VERSION "K24_6MT"

NS_ :

BS_:

BU_: PCM UNKNOWN VSA

BO_ 145 VSA_0x091: 8 VSA
 SG_ YAW_RATE_SENSOR : 7|10@0+ (1,0) [0|1023] "raw"  PCM
 SG_ UNKNOWN_1 : 13|8@0+ (1,0) [0|255] ""  PCM
 SG_ LATERAL_ACCELERATION_SENSOR : 19|10@0+ (1,0) [0|1023] "raw"  PCM
 SG_ UNKNOWN_2 : 20|2@1+ (1,0) [0|3] ""  PCM
 SG_ LONGITUDINAL_ACCELERATION_SENSOR : 25|10@0+ (1,0) [0|1023] "raw"  PCM
 SG_ UNKNOWN_3 : 40|4@1+ (1,0) [0|15] ""  PCM
 SG_ LONGITUDINAL_FAULT_SUMMARY : 44|1@1+ (1,0) [0|1] ""  PCM
 SG_ LATERAL_FAULT_SUMMARY : 45|1@1+ (1,0) [0|1] ""  PCM
 SG_ MONITOR_SUMMARY0 : 46|1@1+ (1,0) [0|1] ""  PCM
 SG_ YAW_FAULT_SUMMARY : 47|1@1+ (1,0) [0|1] ""  PCM
 SG_ MONITOR_CONDITION2 : 48|1@1+ (1,0) [0|1] ""  PCM
 SG_ MONITOR_SUMMARY1 : 49|1@1+ (1,0) [0|1] ""  PCM
 SG_ UNKNOWN_4 : 50|2@1+ (1,0) [0|3] ""  PCM
 SG_ LONGITUDINAL_FAULT_CONDITION : 52|1@1+ (1,0) [0|1] ""  PCM
 SG_ LATERAL_FAULT_CONDITION : 53|1@1+ (1,0) [0|1] ""  PCM
 SG_ MONITOR_CONDITION0 : 54|1@1+ (1,0) [0|1] ""  PCM
 SG_ YAW_FAULT_CONDITION : 55|1@1+ (1,0) [0|1] ""  PCM
 SG_ CHECKSUM : 56|4@1+ (1,0) [0|15] ""  PCM
 SG_ COUNTER : 60|2@1+ (1,0) [0|3] ""  PCM
 SG_ STATUS_BIT_1 : 62|1@1+ (1,0) [0|1] ""  PCM
 SG_ SCALAR_NOT_READY : 63|1@1+ (1,0) [0|1] ""  PCM
VAL_ 145 SCALAR_NOT_READY 1 "NOT_READY" ;

BO_ 420 VSA_0x1A4: 8 VSA
 SG_ MASTER_CYLINDER_PRESSURE_RAW : 3|12@0+ (1,0) [0|4095] "raw"  PCM
 SG_ PRESSURE_RELATED_INHIBIT_1 : 4|1@1+ (1,0) [0|1] ""  PCM
 SG_ PRESSURE_RELATED_INHIBIT_2 : 5|1@1+ (1,0) [0|1] ""  PCM
 SG_ UNKNOWN_1 : 6|2@1+ (1,0) [0|3] ""  PCM
 SG_ VSA_INTERVENTION_ACTIVE : 16|1@1+ (1,0) [0|1] ""  PCM
 SG_ ABS_INTERVENTION_ACTIVE : 17|1@1+ (1,0) [0|1] ""  PCM
 SG_ STATUS_BIT_1 : 18|1@1+ (1,0) [0|1] ""  PCM
 SG_ STATUS_BIT_2 : 19|1@1+ (1,0) [0|1] ""  PCM
 SG_ IDLE_STOP_INHIBIT_VSACASEN : 20|1@1+ (1,0) [0|1] ""  PCM
 SG_ STATUS_BIT_3 : 21|1@1+ (1,0) [0|1] ""  PCM
 SG_ STATUS_BIT_4 : 22|1@1+ (1,0) [0|1] ""  PCM
 SG_ COMPUTER_BRAKING_TBD : 23|1@1+ (1,0) [0|1] ""  PCM
 SG_ UNKNOWN_2 : 24|4@1+ (1,0) [0|15] ""  PCM
 SG_ VSA_DISABLED_TBD : 28|1@1+ (1,0) [0|1] ""  PCM
 SG_ STATUS_BIT_5 : 29|1@1+ (1,0) [0|1] ""  PCM
 SG_ VSA_SYSTEM_UNAVAILABLE_TBD : 30|1@1+ (1,0) [0|1] ""  PCM
 SG_ STATUS_BIT_6 : 31|1@1+ (1,0) [0|1] ""  PCM
 SG_ UNKNOWN_3 : 32|2@1+ (1,0) [0|3] ""  PCM
 SG_ VSA_WATCHDOG_REFRESH_REQUEST : 34|1@1+ (1,0) [0|1] ""  PCM
 SG_ UNKNOWN_4 : 35|5@1+ (1,0) [0|31] ""  PCM
 SG_ UNKNOWN_5 : 40|4@1+ (1,0) [0|15] ""  PCM
 SG_ IDLE_STOP_BRAKE_TRANSITION_TBD : 44|1@1+ (1,0) [0|1] ""  PCM
 SG_ UNKNOWN_6 : 45|3@1+ (1,0) [0|7] ""  PCM
 SG_ UNKNOWN_7 : 48|4@1+ (1,0) [0|15] ""  PCM
 SG_ BRAKE_HOLD_RELATED_TBD : 52|1@1+ (1,0) [0|1] ""  PCM
 SG_ STATUS_BIT_7 : 53|1@1+ (1,0) [0|1] ""  PCM
 SG_ STATUS_BIT_8 : 54|1@1+ (1,0) [0|1] ""  PCM
 SG_ STATUS_BIT_9 : 55|1@1+ (1,0) [0|1] ""  PCM
 SG_ CHECKSUM : 56|4@1+ (1,0) [0|15] ""  PCM
 SG_ COUNTER : 60|2@1+ (1,0) [0|3] ""  PCM
 SG_ STATUS_BIT_10 : 62|1@1+ (1,0) [0|1] ""  PCM
 SG_ STATUS_BIT_11 : 63|1@1+ (1,0) [0|1] ""  PCM
VAL_ 420 IDLE_STOP_INHIBIT_VSACASEN 0 "NORMAL" 1 "INHIBITED" ;

BO_ 426 XXX_0x1AA: 8 VSA
 SG_ UNKNOWN_1 : 7|16@0- (1,0) [-32768|32767] "raw"  PCM
 SG_ UNKNOWN_2 : 16|2@1+ (1,0) [0|3] ""  PCM
 SG_ UNKNOWN_3 : 18|2@1+ (1,0) [0|3] ""  PCM
 SG_ VSA_CATEGORY_STATE_TBD : 20|4@1+ (1,0) [0|15] ""  PCM
 SG_ UNKNOWN_4 : 24|3@1+ (1,0) [0|7] ""  PCM
 SG_ STATUS_BIT_1 : 27|1@1+ (1,0) [0|1] ""  PCM
 SG_ UNKNOWN_5 : 28|4@1+ (1,0) [0|15] ""  PCM
 SG_ UNKNOWN_6 : 32|8@1+ (1,0) [0|255] ""  PCM
 SG_ UNKNOWN_7 : 40|2@1+ (1,0) [0|3] ""  PCM
 SG_ STATUS_BIT_2 : 42|1@1+ (1,0) [0|1] ""  PCM
 SG_ IDLE_STOP_INHIBIT_STARTING_ASSIST_BRAKE : 43|1@1+ (1,0) [0|1] ""  PCM
 SG_ UNKNOWN_8 : 44|2@1+ (1,0) [0|3] ""  PCM
 SG_ STATUS_BIT_3 : 46|1@1+ (1,0) [0|1] ""  PCM
 SG_ IDLE_STOP_INHIBIT_ABS_VSA_UNIT : 47|1@1+ (1,0) [0|1] ""  PCM
 SG_ UNKNOWN_9 : 48|8@1+ (1,0) [0|255] ""  PCM
 SG_ CHECKSUM : 56|4@1+ (1,0) [0|15] ""  PCM
 SG_ COUNTER : 60|2@1+ (1,0) [0|3] ""  PCM
 SG_ STATUS_BIT_4 : 62|1@1+ (1,0) [0|1] ""  PCM
 SG_ STATUS_BIT_5 : 63|1@1+ (1,0) [0|1] ""  PCM
VAL_ 426 IDLE_STOP_INHIBIT_ABS_VSA_UNIT 0 "NORMAL" 1 "INHIBITED" ;
VAL_ 426 IDLE_STOP_INHIBIT_STARTING_ASSIST_BRAKE 0 "INHIBITED" 1 "NORMAL" ;

BO_ 432 VSA_0x1B0: 7 VSA
 SG_ UNKNOWN_1 : 0|8@1+ (1,0) [0|255] ""  PCM
 SG_ UNKNOWN_2 : 8|4@1+ (1,0) [0|15] ""  PCM
 SG_ WHEELS_MOVING : 12|1@1+ (1,0) [0|1] ""  PCM
 SG_ UNKNOWN_3 : 13|2@1+ (1,0) [0|3] ""  PCM
 SG_ STATUS_BIT_1 : 15|1@1+ (1,0) [0|1] ""  PCM
 SG_ UNKNOWN_4 : 16|8@1+ (1,0) [0|255] ""  PCM
 SG_ UNKNOWN_5 : 24|8@1+ (1,0) [0|255] ""  PCM
 SG_ UNKNOWN_6 : 32|3@1+ (1,0) [0|0] ""  PCM
 SG_ STANDSTILL_BRAKE_STATUS_D4B3_TBD : 35|1@1+ (1,0) [0|0] ""  PCM
 SG_ STANDSTILL_BRAKE_STATUS_D4B4_TBD : 36|1@1+ (1,0) [0|0] ""  PCM
 SG_ STANDSTILL_BRAKE_STATUS_D4B5_TBD : 37|1@1+ (1,0) [0|0] ""  PCM
 SG_ STANDSTILL_BRAKE_STATUS_D4B6_TBD : 38|1@1+ (1,0) [0|0] ""  PCM
 SG_ STATUS_BIT_2 : 39|1@1+ (1,0) [0|0] ""  PCM
 SG_ STANDSTILL_STATUS_D5B0_TBD : 40|1@1+ (1,0) [0|0] ""  PCM
 SG_ STANDSTILL_STATUS_D5B1_TBD : 41|1@1+ (1,0) [0|0] ""  PCM
 SG_ STANDSTILL_STATE_D5_BITS3_2_TBD : 42|2@1+ (1,0) [0|0] ""  PCM
 SG_ UNKNOWN_7 : 44|4@1+ (1,0) [0|0] ""  PCM
 SG_ CHECKSUM : 48|4@1+ (1,0) [0|15] ""  PCM
 SG_ COUNTER : 52|2@1+ (1,0) [0|3] ""  PCM
 SG_ PROTOCOL_FLAGS : 54|2@1+ (1,0) [0|3] ""  PCM

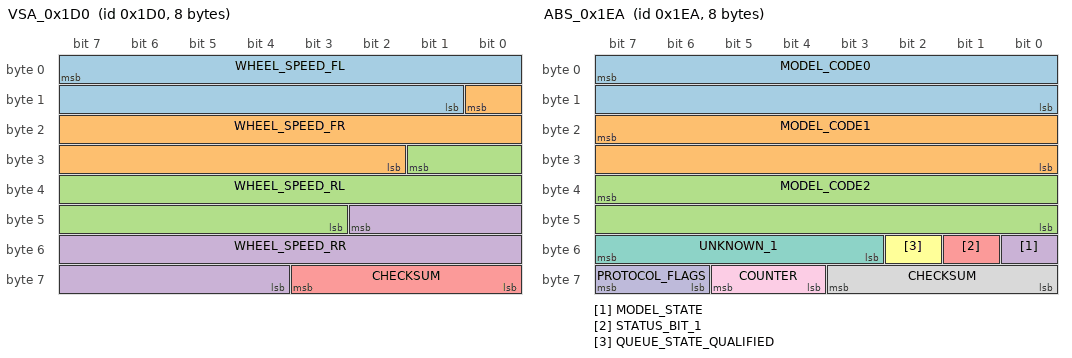
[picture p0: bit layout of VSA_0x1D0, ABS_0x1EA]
BO_ 464 VSA_0x1D0: 8 VSA
 SG_ WHEEL_SPEED_FL : 7|15@0+ (0.00993422,0) [0|325.51458674] "km/h"  PCM
 SG_ WHEEL_SPEED_FR : 8|15@0+ (0.00993422,0) [0|325.51458674] "km/h"  PCM
 SG_ WHEEL_SPEED_RL : 25|15@0+ (0.00993422,0) [0|325.51458674] "km/h"  PCM
 SG_ WHEEL_SPEED_RR : 42|15@0+ (0.00993422,0) [0|325.51458674] "km/h"  PCM
 SG_ CHECKSUM : 56|4@1+ (1,0) [0|15] ""  PCM

BO_ 490 ABS_0x1EA: 8 VSA
 SG_ MODEL_CODE0 : 7|16@0+ (1,0) [0|65535] "raw"  UNKNOWN
 SG_ MODEL_CODE1 : 23|16@0+ (1,0) [0|65535] "raw"  UNKNOWN
 SG_ MODEL_CODE2 : 39|16@0+ (1,0) [0|65535] "raw"  UNKNOWN
 SG_ MODEL_STATE : 48|1@1+ (1,0) [0|1] ""  UNKNOWN
 SG_ STATUS_BIT_1 : 49|1@1+ (1,0) [0|1] ""  UNKNOWN
 SG_ QUEUE_STATE_QUALIFIED : 50|1@1+ (1,0) [0|1] ""  UNKNOWN
 SG_ UNKNOWN_1 : 51|5@1+ (1,0) [0|31] ""  UNKNOWN
 SG_ CHECKSUM : 56|4@1+ (1,0) [0|15] ""  UNKNOWN
 SG_ COUNTER : 60|2@1+ (1,0) [0|3] ""  UNKNOWN
 SG_ PROTOCOL_FLAGS : 62|2@1+ (1,0) [0|3] ""  UNKNOWN

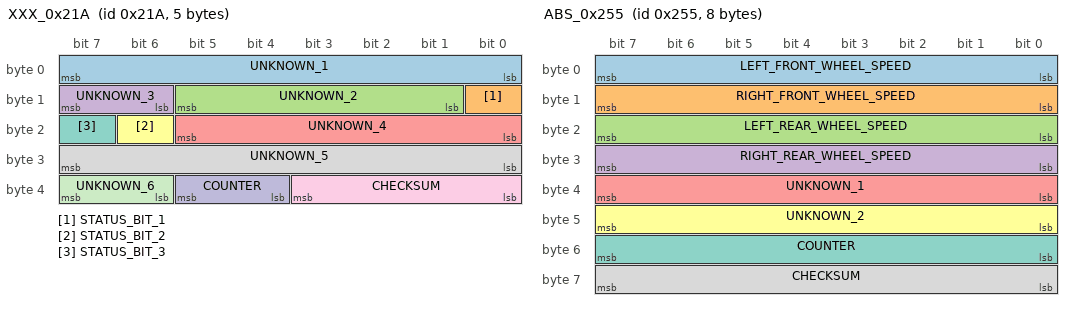
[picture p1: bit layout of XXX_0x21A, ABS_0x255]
BO_ 538 XXX_0x21A: 5 VSA
 SG_ UNKNOWN_1 : 0|8@1+ (1,0) [0|255] ""  PCM
 SG_ STATUS_BIT_1 : 8|1@1+ (1,0) [0|1] ""  PCM
 SG_ UNKNOWN_2 : 9|5@1+ (1,0) [0|31] ""  PCM
 SG_ UNKNOWN_3 : 14|2@1+ (1,0) [0|3] ""  PCM
 SG_ UNKNOWN_4 : 16|6@1+ (1,0) [0|63] ""  PCM
 SG_ STATUS_BIT_2 : 22|1@1+ (1,0) [0|1] ""  PCM
 SG_ STATUS_BIT_3 : 23|1@1+ (1,0) [0|1] ""  PCM
 SG_ UNKNOWN_5 : 24|8@1+ (1,0) [0|255] ""  PCM
 SG_ CHECKSUM : 32|4@1+ (1,0) [0|15] ""  PCM
 SG_ COUNTER : 36|2@1+ (1,0) [0|3] ""  PCM
 SG_ UNKNOWN_6 : 38|2@1+ (1,0) [0|3] ""  PCM

BO_ 597 ABS_0x255: 8 VSA
 SG_ LEFT_FRONT_WHEEL_SPEED : 0|8@1+ (1,0) [0|255] "raw"  UNKNOWN
 SG_ RIGHT_FRONT_WHEEL_SPEED : 8|8@1+ (1,0) [0|255] "raw"  UNKNOWN
 SG_ LEFT_REAR_WHEEL_SPEED : 16|8@1+ (1,0) [0|255] "raw"  UNKNOWN
 SG_ RIGHT_REAR_WHEEL_SPEED : 24|8@1+ (1,0) [0|255] "raw"  UNKNOWN
 SG_ UNKNOWN_1 : 32|8@1+ (1,0) [0|255] ""  UNKNOWN
 SG_ UNKNOWN_2 : 40|8@1+ (1,0) [0|255] ""  UNKNOWN
 SG_ COUNTER : 48|8@1+ (1,0) [0|255] ""  UNKNOWN
 SG_ CHECKSUM : 56|8@1+ (1,0) [0|255] ""  UNKNOWN

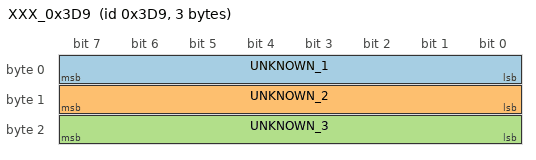
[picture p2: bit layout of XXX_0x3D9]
BO_ 985 XXX_0x3D9: 3 VSA
 SG_ UNKNOWN_1 : 0|8@1+ (1,0) [0|255] ""  UNKNOWN
 SG_ UNKNOWN_2 : 8|8@1+ (1,0) [0|255] ""  UNKNOWN
 SG_ UNKNOWN_3 : 16|8@1+ (1,0) [0|255] ""  UNKNOWN
